AUTOSAR XML (schema 00050)
package /ComponentTypes
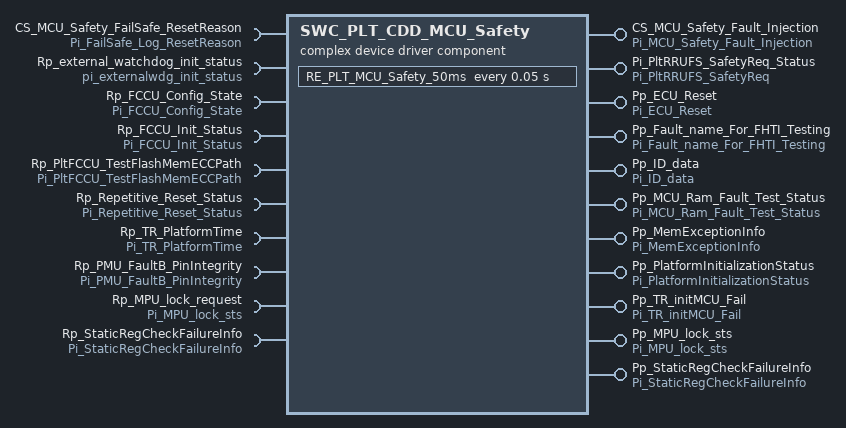
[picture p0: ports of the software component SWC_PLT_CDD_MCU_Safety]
  complex device driver sw component type SWC_PLT_CDD_MCU_Safety
    9 x provide port:
      CS_MCU_Safety_Fault_Injection: server-com-spec{operation=Read, queue-length=1}, provided-interface=Pi_MCU_Safety_Fault_Injection
      Pi_PltRRUFS_SafetyReq_Status: provided-interface=Pi_PltRRUFS_SafetyReq
        provided-com-specs:
          operation=ECC_CacheMemory_SafetyCore_Disable, queue-length=1
          operation=ECC_CacheMemory_SafetyCore_Enable, queue-length=1
          operation=ECC_CacheMemory_SafetyCore_Status, queue-length=1
          operation=ECC_FlashMemory_Fault_Report_Check, queue-length=1
          operation=RCCU_CheckerCore_Status, queue-length=1
          operation=RRU_FS_InitTest, queue-length=1
      Pp_ECU_Reset: server-com-spec{operation=ECU_Soft_Reset, queue-length=1}, provided-interface=Pi_ECU_Reset
      Pp_Fault_name_For_FHTI_Testing: nonqueued-sender-com-spec{data-element=De_Fault_name_FHTI, init-value=0}, provided-interface=Pi_Fault_name_For_FHTI_Testing
      Pp_ID_data: nonqueued-sender-com-spec{data-element=De_ID_data, init-value=constant-reference=C_ID_data}, provided-interface=Pi_ID_data
      Pp_MCU_Ram_Fault_Test_Status: nonqueued-sender-com-spec{data-element=De_MCU_Ram_Fault_Test_Status, init-value=0}, provided-interface=Pi_MCU_Ram_Fault_Test_Status
      Pp_MemExceptionInfo: nonqueued-sender-com-spec{data-element=De_MemExceptionInfo, init-value=constant-reference=C_MemExceptionInfo}, provided-interface=Pi_MemExceptionInfo
      Pp_PlatformInitializationStatus: nonqueued-sender-com-spec{data-element=De_MCU_InitializationStatus, init-value=constant-reference=C_MCU_initlaisation_NOTCompleted_T}, provided-interface=Pi_PlatformInitializationStatus
      Pp_TR_initMCU_Fail: nonqueued-sender-com-spec=De_TR_InitMCU_fail, provided-interface=Pi_TR_initMCU_Fail
    9 x require port:
      CS_MCU_Safety_FailSafe_ResetReason: client-com-spec=FailSafe_Log_ResetReason, required-interface=Pi_FailSafe_Log_ResetReason
      Rp_external_watchdog_init_status: nonqueued-receiver-com-spec{data-element=de_wdginit_status, filter=data-filter-type=ALWAYS, init-value=0}, required-interface=pi_externalwdg_init_status
      Rp_FCCU_Config_State: nonqueued-receiver-com-spec{data-element=FCCU_Config_State, filter=data-filter-type=ALWAYS, init-value=0}, required-interface=Pi_FCCU_Config_State
      Rp_FCCU_Init_Status: nonqueued-receiver-com-spec{data-element=De_Init_Status, filter=data-filter-type=ALWAYS, init-value=0}, required-interface=Pi_FCCU_Init_Status
      Rp_PltFCCU_TestFlashMemECCPath: client-com-spec=FCCU_TestFlashMemECCPath, required-interface=Pi_PltFCCU_TestFlashMemECCPath
      Rp_Repetitive_Reset_Status: nonqueued-receiver-com-spec{data-element=De_Repetitive_Reset_Status, filter=data-filter-type=ALWAYS, init-value=85}, required-interface=Pi_Repetitive_Reset_Status
      Rp_TR_PlatformTime: nonqueued-receiver-com-spec{data-element=De_PlatformTime, filter=data-filter-type=ALWAYS, init-value=85}, required-interface=Pi_TR_PlatformTime
      Rp_PMU_FaultB_PinIntegrity: nonqueued-receiver-com-spec{data-element=De_PMU_FaultB_PinIntegrityStat, filter=data-filter-type=ALWAYS, init-value=0}, required-interface=Pi_PMU_FaultB_PinIntegrity
      Rp_MPU_lock_request: nonqueued-receiver-com-spec{data-element=De_MPU_lock_sts, filter=data-filter-type=ALWAYS, init-value=0}, required-interface=Pi_MPU_lock_sts
    provide port Pp_MPU_lock_sts: nonqueued-sender-com-spec{data-element=De_MPU_lock_sts, init-value=0}, provided-interface=Pi_MPU_lock_sts
    require port Rp_StaticRegCheckFailureInfo: nonqueued-receiver-com-spec{data-element=De_StaticRegCheckFailureInfo, filter=data-filter-type=ALWAYS, init-value=35 x 0}, required-interface=Pi_StaticRegCheckFailureInfo
    provide port Pp_StaticRegCheckFailureInfo: nonqueued-sender-com-spec{data-element=De_StaticRegCheckFailureInfo, init-value=35 x 0}, provided-interface=Pi_StaticRegCheckFailureInfo
    behavior SWC_PLT_CDD_MCU_Safety_InternalBehavior: handle-termination-and-restart=NO-SUPPORT
      7 x operation invoked event:
        OIT_CS_MCU_Safety_Fault_Injection_Read_CS_MCU_Safety_Fault_Injection_Read: start-on-event=CS_MCU_Safety_Fault_Injection, operation=CS_MCU_Safety_Fault_Injection.Read
        OIT_Pi_PltRRUFS_SafetyReq_Status_ECC_CacheMemory_SafetyCore_Disable_Pi_PltRRUFS_SafetyReq_Status_ECC_CacheMemory_SafetyCA86BA9B6: start-on-event=ECC_CacheMemory_SafetyCore_Disable, operation=Pi_PltRRUFS_SafetyReq_Status.ECC_CacheMemory_SafetyCore_Disable
        OIT_Pi_PltRRUFS_SafetyReq_Status_ECC_CacheMemory_SafetyCore_Enable_Pi_PltRRUFS_SafetyReq_Status_ECC_CacheMemory_SafetyCo27762F73: start-on-event=ECC_CacheMemory_SafetyCore_Enable, operation=Pi_PltRRUFS_SafetyReq_Status.ECC_CacheMemory_SafetyCore_Enable
        OIT_Pi_PltRRUFS_SafetyReq_Status_ECC_CacheMemory_SafetyCore_Status_Pi_PltRRUFS_SafetyReq_Status_ECC_CacheMemory_SafetyCoAEF3F286: start-on-event=ECC_CacheMemory_SafetyCore_Status, operation=Pi_PltRRUFS_SafetyReq_Status.ECC_CacheMemory_SafetyCore_Status
        OIT_Pi_PltRRUFS_SafetyReq_Status_ECC_FlashMemory_Fault_Report_Check_Pi_PltRRUFS_SafetyReq_Status_ECC_FlashMemory_Fault_R4B6A5298: start-on-event=ECC_FlashMemory_Fault_Report_Check, operation=Pi_PltRRUFS_SafetyReq_Status.ECC_FlashMemory_Fault_Report_Check
        OIT_Pp_ECU_Reset_ECU_Soft_Reset_Pp_ECU_Reset_ECU_Soft_Reset: start-on-event=ECU_Soft_Reset, operation=Pp_ECU_Reset.ECU_Soft_Reset
        OIT_Pi_PltRRUFS_SafetyReq_Status_RCCU_CheckerCore_Status_Pi_PltRRUFS_SafetyReq_Status_RCCU_CheckerCore_Status: start-on-event=RCCU_CheckerCore_Status, operation=Pi_PltRRUFS_SafetyReq_Status.RCCU_CheckerCore_Status
      timing event TMT_RE_PLT_MCU_Safety_50ms: start-on-event=RE_PLT_MCU_Safety_50ms, period=0.05
      init event SWC_PLT_CDD_RRU_FuncSafety_InitEvent: start-on-event=RE_PLT_MCU_Safety_Init
      operation invoked event OIT_Pi_PltRRUFS_SafetyReq_Status_RRU_FS_InitTest_Pi_PltRRUFS_SafetyReq_Status_RRU_FS_InitTest: start-on-event=RRU_FS_InitTest, operation=Pi_PltRRUFS_SafetyReq_Status.RRU_FS_InitTest
      10 x runnable:
        CS_MCU_Safety_Fault_Injection
        ECC_CacheMemory_SafetyCore_Disable
        ECC_CacheMemory_SafetyCore_Enable
        ECC_CacheMemory_SafetyCore_Status
        ECC_FlashMemory_Fault_Report_Check
          sync call SC_Rp_PltFCCU_TestFlashMemECCPath_FCCU_TestFlashMemECCPath: operation=Rp_PltFCCU_TestFlashMemECCPath.FCCU_TestFlashMemECCPath, timeout=0
        ECU_Soft_Reset: can-be-invoked-concurrently=true
        RCCU_CheckerCore_Status
        RE_PLT_MCU_Safety_50ms
          data-receive-point-by-arguments:
            access REC_Rp_FCCU_Init_Status_De_Init_Status: accessed-variable=Rp_FCCU_Init_Status.De_Init_Status
            access REC_Rp_MPU_lock_request_De_MPU_lock_sts: accessed-variable=Rp_MPU_lock_request.De_MPU_lock_sts
            access REC_Rp_StaticRegCheckFailureInfo_De_StaticRegCheckFailureInfo: accessed-variable=Rp_StaticRegCheckFailureInfo.De_StaticRegCheckFailureInfo
          data-send-points:
            4 x access:
              SEND_Pp_Fault_name_For_FHTI_Testing_De_Fault_name_FHTI: accessed-variable=Pp_Fault_name_For_FHTI_Testing.De_Fault_name_FHTI
              SEND_Pp_MemExceptionInfo_De_MemExceptionInfo: accessed-variable=Pp_MemExceptionInfo.De_MemExceptionInfo
              SEND_Pp_MPU_lock_sts_De_MPU_lock_sts: accessed-variable=Pp_MPU_lock_sts.De_MPU_lock_sts
              SEND_Pp_StaticRegCheckFailureInfo_De_StaticRegCheckFailureInfo: accessed-variable=Pp_StaticRegCheckFailureInfo.De_StaticRegCheckFailureInfo
          sync call SC_CS_MCU_Safety_FailSafe_ResetReason_FailSafe_Log_ResetReason: operation=CS_MCU_Safety_FailSafe_ResetReason.FailSafe_Log_ResetReason, timeout=0
        RE_PLT_MCU_Safety_Init
          data-receive-point-by-arguments:
            5 x access:
              REC_Rp_external_watchdog_init_status_de_wdginit_status: accessed-variable=Rp_external_watchdog_init_status.de_wdginit_status
              REC_Rp_FCCU_Config_State_FCCU_Config_State: accessed-variable=Rp_FCCU_Config_State.FCCU_Config_State
              REC_Rp_Repetitive_Reset_Status_De_Repetitive_Reset_Status: accessed-variable=Rp_Repetitive_Reset_Status.De_Repetitive_Reset_Status
              REC_Rp_TR_PlatformTime_De_TR_PlatformTime: accessed-variable=Rp_TR_PlatformTime.De_PlatformTime
              REC_Rp_PMU_FaultB_PinIntegrity_De_PMU_FaultB_PinIntegrityStat: accessed-variable=Rp_PMU_FaultB_PinIntegrity.De_PMU_FaultB_PinIntegrityStat
          data-send-points:
            4 x access:
              SEND_Pp_ID_data_De_ID_data: accessed-variable=Pp_ID_data.De_ID_data
              SEND_Pp_MCU_Ram_Fault_Test_Status_De_MCU_Ram_Fault_Test_Status: accessed-variable=Pp_MCU_Ram_Fault_Test_Status.De_MCU_Ram_Fault_Test_Status
              SEND_Pp_PlatformInitializationStatus_De_MCU_InitializationStatus: accessed-variable=Pp_PlatformInitializationStatus.De_MCU_InitializationStatus
              SEND_Pp_TR_initMCU_Fail_Dt_TR_InitMCU_fail: accessed-variable=Pp_TR_initMCU_Fail.De_TR_InitMCU_fail
        RRU_FS_InitTest
  swc implementation SWC_PLT_CDD_MCU_Safety_Implementation: behavior=SWC_PLT_CDD_MCU_Safety_InternalBehavior
    code-descriptors:
      code Default: artifact-descriptors=autosar-engineering-object=category=SWSRC
